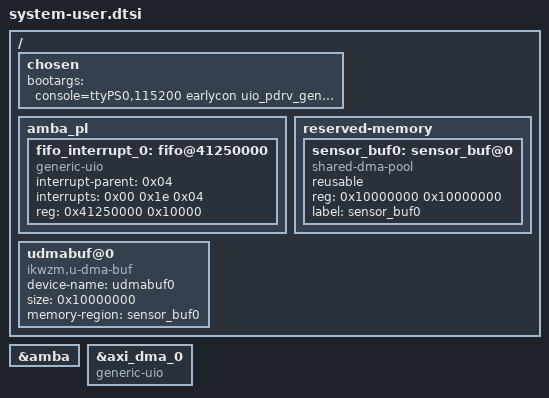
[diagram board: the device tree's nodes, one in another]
/include/ "system-conf.dtsi"
/ {
  chosen {
    bootargs = "console=ttyPS0,115200 earlycon uio_pdrv_genirq.of_id=generic-uio root=/dev/mmcblk0p2 rw rootwait";
  };

  amba_pl: amba_pl {
    fifo_interrupt_0: fifo@41250000 {
      #dma-cells = <0x01>;
      compatible = "generic-uio";
      interrupt-parent = <0x04>;
      interrupts = <0x00 0x1e 0x04>;
      reg = <0x41250000 0x10000>;
    };
  };

  reserved-memory {
    #address-cells = <1>;
    #size-cells = <1>;
    ranges;
    sensor_buf0: sensor_buf@0 {
      compatible = "shared-dma-pool";
      reusable;
      reg = <0x10000000 0x10000000>;
      label = "sensor_buf0";
    };
  };

  udmabuf@0 {
    compatible = "ikwzm,u-dma-buf";
    device-name = "udmabuf0";
    size = <0x10000000>; // 256MiB
    memory-region = <&sensor_buf0>;
  };
};

&amba {
  /delete-node/ dmac@f8003000;
};

&axi_dma_0 {
  compatible = "generic-uio";
  /delete-property/ clock-names;
  /delete-property/ clocks;
  /delete-property/ interrupt-names;
  /delete-property/ xlnx,addrwidth;
  /delete-property/ xlnx,sg-length-width;
  /delete-node/ dma-channel@40400030;
};
